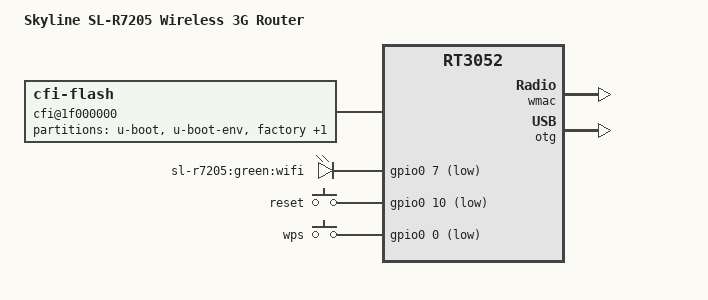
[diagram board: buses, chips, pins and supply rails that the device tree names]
/dts-v1/;

#include "rt3050.dtsi"

/ {
	compatible = "SL-R7205", "ralink,rt3052-soc";
	model = "Skyline SL-R7205 Wireless 3G Router";

	cfi@1f000000 {
		compatible = "cfi-flash";
		reg = <0x1f000000 0x800000>;
		bank-width = <2>;
		device-width = <2>;
		#address-cells = <1>;
		#size-cells = <1>;

		partition@0 {
			label = "u-boot";
			reg = <0x0 0x30000>;
			read-only;
		};

		partition@30000 {
			label = "u-boot-env";
			reg = <0x30000 0x10000>;
			read-only;
		};

		factory: partition@40000 {
			label = "factory";
			reg = <0x40000 0x10000>;
			read-only;
		};

		partition@50000 {
			label = "firmware";
			reg = <0x50000 0x3b0000>;
		};
	};

	gpio-leds {
		compatible = "gpio-leds";

		wifi {
			label = "sl-r7205:green:wifi";
			gpios = <&gpio0 7 1>;
		};
	};

	gpio-keys-polled {
		compatible = "gpio-keys-polled";
		#address-cells = <1>;
		#size-cells = <0>;
		poll-interval = <20>;

		reset {
			label = "reset";
			gpios = <&gpio0 10 1>;
			linux,code = <0x198>;
		};

		wps {
			label = "wps";
			gpios = <&gpio0 0 1>;
			linux,code = <0x211>;
		};
	};
};

&pinctrl {
	state_default: pinctrl0 {
		gpio {
			ralink,group = "spi", "i2c", "jtag", "rgmii", "mdio", "uartf";
			ralink,function = "gpio";
		};
	};
};

&ethernet {
	mtd-mac-address = <&factory 0x4>;
};

&esw {
	mediatek,portmap = <0x3e>;
};

&wmac {
	ralink,mtd-eeprom = <&factory 0>;
};

&otg {
	status = "okay";
};
